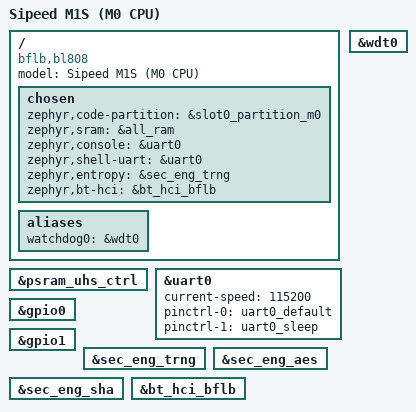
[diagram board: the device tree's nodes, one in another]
/*
 * Copyright The Zephyr Project Contributors
 *
 * SPDX-License-Identifier: Apache-2.0
 */

#include <bflb/bl808-m0.dtsi>
#include <bflb/bl808_em_32kb.dtsi>
#include "m1s_common.dtsi"

/ {
	model = "Sipeed M1S (M0 CPU)";
	compatible = "bflb,bl808";

	chosen {
		zephyr,code-partition = &slot0_partition_m0;
		zephyr,sram = &all_ram;
		zephyr,console = &uart0;
		zephyr,shell-uart = &uart0;
		zephyr,entropy = &sec_eng_trng;
		zephyr,bt-hci = &bt_hci_bflb;
	};

	aliases {
		watchdog0 = &wdt0;
	};
};

&psram_uhs_ctrl {
	status = "okay";
};

&uart0 {
	status = "okay";
	current-speed = <115200>;

	pinctrl-0 = <&uart0_default>;
	pinctrl-1 = <&uart0_sleep>;
	pinctrl-names = "default", "sleep";
};

&gpio0 {
	status = "okay";
};

&gpio1 {
	status = "okay";
};

&wdt0 {
	status = "okay";
};

&sec_eng_trng {
	status = "okay";
};

&sec_eng_aes {
	status = "okay";
};

&sec_eng_sha {
	status = "okay";
};

&bt_hci_bflb {
	status = "okay";
};
